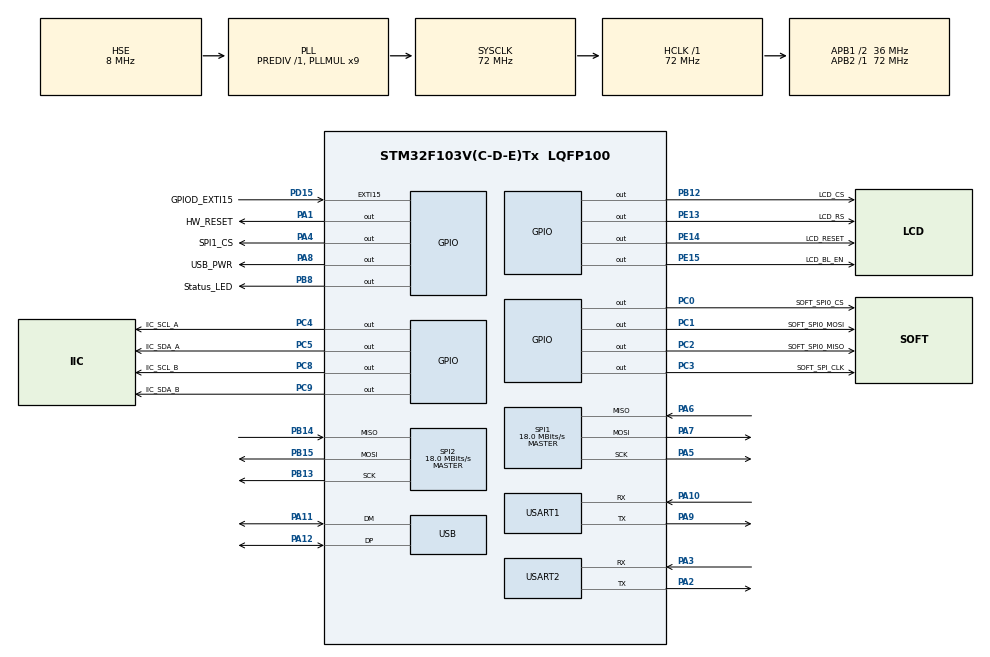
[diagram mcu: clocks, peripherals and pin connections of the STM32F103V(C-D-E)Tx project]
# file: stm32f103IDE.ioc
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FREERTOS.Tasks01=defaultTask,0,128,StartDefaultTask,Default,NULL
FREERTOS.configTOTAL_HEAP_SIZE=30720
Mcu.Family=STM32F1
Mcu.Name=STM32F103V(C-D-E)Tx
Mcu.Package=LQFP100
NVIC.PriorityGroup=NVIC_PRIORITYGROUP_4
NVIC.TIM8_UP_IRQn=true\:0\:0\:false\:false\:true\:false\:false\:true
NVIC.TimeBase=TIM8_UP_IRQn
NVIC.TimeBaseIP=TIM8
NVIC.USB_LP_CAN1_RX0_IRQn=true\:5\:0\:false\:false\:true\:true\:false\:true
OSC_IN.Mode=HSE-External-Oscillator
OSC_IN.Signal=RCC_OSC_IN
OSC_OUT.Mode=HSE-External-Oscillator
OSC_OUT.Signal=RCC_OSC_OUT
PA1.GPIO_Label=HW_RESET
PA1.Signal=GPIO_Output
PA10.Mode=Asynchronous
PA10.Signal=USART1_RX
PA11.Mode=Device
PA11.Signal=USB_DM
PA12.Mode=Device
PA12.Signal=USB_DP
PA13.Mode=Serial_Wire
PA13.Signal=SYS_JTMS-SWDIO
PA14.Mode=Serial_Wire
PA14.Signal=SYS_JTCK-SWCLK
PA2.Mode=Asynchronous
PA2.Signal=USART2_TX
PA3.Mode=Asynchronous
PA3.Signal=USART2_RX
PA4.GPIO_Label=SPI1_CS
PA4.GPIO_ModeDefaultOutputPP=GPIO_MODE_OUTPUT_PP
PA4.GPIO_Speed=GPIO_SPEED_FREQ_HIGH
PA4.PinState=GPIO_PIN_SET
PA4.Signal=GPIO_Output
PA5.Mode=Full_Duplex_Master
PA5.Signal=SPI1_SCK
PA6.Mode=Full_Duplex_Master
PA6.Signal=SPI1_MISO
PA7.Mode=Full_Duplex_Master
PA7.Signal=SPI1_MOSI
PA8.GPIO_Label=USB_PWR
PA8.GPIO_ModeDefaultOutputPP=GPIO_MODE_OUTPUT_PP
PA8.GPIO_PuPd=GPIO_PULLUP
PA8.GPIO_Speed=GPIO_SPEED_FREQ_LOW
PA8.PinState=GPIO_PIN_SET
PA8.Signal=GPIO_Output
PA9.Mode=Asynchronous
PA9.Signal=USART1_TX
PB12.GPIO_Label=LCD_CS
PB12.Signal=GPIO_Output
PB13.Mode=Full_Duplex_Master
PB13.Signal=SPI2_SCK
PB14.Mode=Full_Duplex_Master
PB14.Signal=SPI2_MISO
PB15.Mode=Full_Duplex_Master
PB15.Signal=SPI2_MOSI
PB8.GPIO_Label=Status_LED
PB8.PinState=GPIO_PIN_RESET
PB8.Signal=GPIO_Output
PC0.GPIO_Label=SOFT_SPI0_CS
PC0.GPIO_ModeDefaultOutputPP=GPIO_MODE_OUTPUT_PP
PC0.GPIO_PuPd=GPIO_NOPULL
PC0.GPIO_Speed=GPIO_SPEED_FREQ_HIGH
PC0.PinState=GPIO_PIN_SET
PC0.Signal=GPIO_Output
PC1.GPIO_Label=SOFT_SPI0_MOSI
PC1.GPIO_Speed=GPIO_SPEED_FREQ_HIGH
PC1.PinState=GPIO_PIN_RESET
PC1.Signal=GPIO_Output
PC14-OSC32_IN.Mode=LSE-External-Oscillator
PC14-OSC32_IN.Signal=RCC_OSC32_IN
PC15-OSC32_OUT.Mode=LSE-External-Oscillator
PC15-OSC32_OUT.Signal=RCC_OSC32_OUT
PC2.GPIO_Label=SOFT_SPI0_MISO
PC2.GPIO_Speed=GPIO_SPEED_FREQ_HIGH
PC2.Signal=GPIO_Output
PC3.GPIO_Label=SOFT_SPI_CLK
PC3.GPIO_ModeDefaultOutputPP=GPIO_MODE_OUTPUT_PP
PC3.GPIO_PuPd=GPIO_PULLUP
PC3.GPIO_Speed=GPIO_SPEED_FREQ_HIGH
PC3.PinState=GPIO_PIN_RESET
PC3.Signal=GPIO_Output
PC4.GPIO_Label=IIC_SCL_A
PC4.GPIO_ModeDefaultOutputPP=GPIO_MODE_OUTPUT_OD
PC4.GPIO_Speed=GPIO_SPEED_FREQ_MEDIUM
PC4.PinState=GPIO_PIN_SET
PC4.Signal=GPIO_Output
PC5.GPIO_Label=IIC_SDA_A
PC5.GPIO_ModeDefaultOutputPP=GPIO_MODE_OUTPUT_OD
PC5.GPIO_Speed=GPIO_SPEED_FREQ_HIGH
PC5.PinState=GPIO_PIN_SET
PC5.Signal=GPIO_Output
PC8.GPIO_Label=IIC_SCL_B
PC8.GPIO_ModeDefaultOutputPP=GPIO_MODE_OUTPUT_OD
PC8.GPIO_Speed=GPIO_SPEED_FREQ_HIGH
PC8.PinState=GPIO_PIN_SET
PC8.Signal=GPIO_Output
PC9.GPIO_Label=IIC_SDA_B
PC9.GPIO_ModeDefaultOutputPP=GPIO_MODE_OUTPUT_OD
PC9.GPIO_Speed=GPIO_SPEED_FREQ_HIGH
PC9.PinState=GPIO_PIN_SET
PC9.Signal=GPIO_Output
PD15.GPIO_Label=GPIOD_EXTI15
PD15.Signal=GPXTI15
PE13.GPIO_Label=LCD_RS
PE13.Signal=GPIO_Output
PE14.GPIO_Label=LCD_RESET
PE14.Signal=GPIO_Output
PE15.GPIO_Label=LCD_BL_EN
PE15.Signal=GPIO_Output
ProjectManager.HeapSize=0x600
ProjectManager.StackSize=0x400
ProjectManager.TargetToolchain=STM32CubeIDE
RCC.AHBFreq_Value=72000000
RCC.APB1CLKDivider=RCC_HCLK_DIV2
RCC.APB1Freq_Value=36000000
RCC.APB1TimFreq_Value=72000000
RCC.APB2Freq_Value=72000000
RCC.APB2TimFreq_Value=72000000
RCC.EnbaleCSS=true
RCC.HCLKFreq_Value=72000000
RCC.PLLMUL=RCC_PLL_MUL9
RCC.SYSCLKFreq_VALUE=72000000
RCC.SYSCLKSource=RCC_SYSCLKSOURCE_PLLCLK
RCC.USBFreq_Value=48000000
RCC.USBPrescaler=RCC_USBCLKSOURCE_PLL_DIV1_5
SPI1.BaudRatePrescaler=SPI_BAUDRATEPRESCALER_4
SPI1.CalculateBaudRate=18.0 MBits/s
SPI1.Direction=SPI_DIRECTION_2LINES
SPI1.Mode=SPI_MODE_MASTER
SPI1.VirtualType=VM_MASTER
SPI2.CalculateBaudRate=18.0 MBits/s
SPI2.Direction=SPI_DIRECTION_2LINES
SPI2.Mode=SPI_MODE_MASTER
SPI2.VirtualType=VM_MASTER
USART1.VirtualMode=VM_ASYNC
USART2.VirtualMode=VM_ASYNC
USB_DEVICE.CLASS_NAME_FS=MSC
USB_DEVICE.MSC_MEDIA_PACKET=0x1000
USB_DEVICE.USBD_DEBUG_LEVEL=3
USB_DEVICE.USBD_MAX_NUM_CONFIGURATION=2
USB_DEVICE.USBD_MAX_NUM_INTERFACES=2
USB_DEVICE.USBD_MAX_STR_DESC_SIZ=128
USB_DEVICE.VirtualMode=Msc
USB_DEVICE.VirtualModeFS=Msc_FS
VP_FREERTOS_VS_CMSIS_V1.Mode=CMSIS_V1
VP_SYS_VS_tim8.Mode=TIM8
VP_USB_DEVICE_VS_USB_DEVICE_MSC_FS.Mode=MSC_FS
board=custom

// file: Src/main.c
/* USER CODE BEGIN Header */
/**
  ******************************************************************************
  * @file           : main.c
  * @brief          : Main program body
  ******************************************************************************
  * @attention
  *
  * <h2><center>&copy; Copyright (c) 2019 STMicroelectronics.
  * All rights reserved.</center></h2>
  *
  * This software component is licensed by ST under BSD 3-Clause license,
  * the "License"; You may not use this file except in compliance with the
  * License. You may obtain a copy of the License at:
  *                        opensource.org/licenses/BSD-3-Clause
  *
  ******************************************************************************
  */
/* USER CODE END Header */

#include "main.h"
#include "cmsis_os.h"
#include "spi.h"
#include "usart.h"
#include "usb_device.h"
#include "gpio.h"

/* USER CODE BEGIN Includes */
#include "bsp_eeprom.h"
/* USER CODE END Includes */

void SystemClock_Config(void);
void MX_FREERTOS_Init(void);

int main(void)
{

  /* MCU Configuration--------------------------------------------------------*/

  /* Reset of all peripherals, Initializes the Flash interface and the Systick. */
  HAL_Init();

  /* Configure the system clock */
  SystemClock_Config();

  /* Initialize all configured peripherals */
  MX_GPIO_Init();
  MX_SPI1_Init();
  MX_SPI2_Init();
  MX_USART1_UART_Init();
  MX_USART2_UART_Init();
  /* USER CODE BEGIN 2 */
  printf("program start\r\n");

  //eeprom_Test();
  read_Manufacturer_Device_ID();
  //flash_Test();

  //mount_disk();
  Lcd_Init();

  printf("program end\r\n");
  /* USER CODE END 2 */

  /* Call init function for freertos objects (in freertos.c) */
  MX_FREERTOS_Init();

  /* Start scheduler */
  osKernelStart();

  /* We should never get here as control is now taken by the scheduler */

  /* Infinite loop */
  while (1)
  {

  }
}

void SystemClock_Config(void)
{
  RCC_OscInitTypeDef RCC_OscInitStruct = {0};
  RCC_ClkInitTypeDef RCC_ClkInitStruct = {0};
  RCC_PeriphCLKInitTypeDef PeriphClkInit = {0};

  /** Initializes the CPU, AHB and APB busses clocks
  */
  RCC_OscInitStruct.OscillatorType = RCC_OSCILLATORTYPE_HSE;
  RCC_OscInitStruct.HSEState = RCC_HSE_ON;
  RCC_OscInitStruct.HSEPredivValue = RCC_HSE_PREDIV_DIV1;
  RCC_OscInitStruct.HSIState = RCC_HSI_ON;
  RCC_OscInitStruct.PLL.PLLState = RCC_PLL_ON;
  RCC_OscInitStruct.PLL.PLLSource = RCC_PLLSOURCE_HSE;
  RCC_OscInitStruct.PLL.PLLMUL = RCC_PLL_MUL9;
  if (HAL_RCC_OscConfig(&RCC_OscInitStruct) != HAL_OK)
  {
    Error_Handler();
  }
  /** Initializes the CPU, AHB and APB busses clocks
  */
  RCC_ClkInitStruct.ClockType = RCC_CLOCKTYPE_HCLK|RCC_CLOCKTYPE_SYSCLK
                              |RCC_CLOCKTYPE_PCLK1|RCC_CLOCKTYPE_PCLK2;
  RCC_ClkInitStruct.SYSCLKSource = RCC_SYSCLKSOURCE_PLLCLK;
  RCC_ClkInitStruct.AHBCLKDivider = RCC_SYSCLK_DIV1;
  RCC_ClkInitStruct.APB1CLKDivider = RCC_HCLK_DIV2;
  RCC_ClkInitStruct.APB2CLKDivider = RCC_HCLK_DIV1;

  if (HAL_RCC_ClockConfig(&RCC_ClkInitStruct, FLASH_LATENCY_2) != HAL_OK)
  {
    Error_Handler();
  }
  PeriphClkInit.PeriphClockSelection = RCC_PERIPHCLK_USB;
  PeriphClkInit.UsbClockSelection = RCC_USBCLKSOURCE_PLL_DIV1_5;
  if (HAL_RCCEx_PeriphCLKConfig(&PeriphClkInit) != HAL_OK)
  {
    Error_Handler();
  }
  /** Enables the Clock Security System
  */
  HAL_RCC_EnableCSS();
}

void HAL_TIM_PeriodElapsedCallback(TIM_HandleTypeDef *htim)
{
  if (htim->Instance == TIM8) {
    HAL_IncTick();
  }
}

void Error_Handler(void)
{
  /* USER CODE BEGIN Error_Handler_Debug */
  /* User can add his own implementation to report the HAL error return state */
	printf("Error_Handler\r\n");
  /* USER CODE END Error_Handler_Debug */
}

/************************ (C) COPYRIGHT STMicroelectronics *****END OF FILE****/

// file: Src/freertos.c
/* USER CODE BEGIN Header */
/**
  ******************************************************************************
  * File Name          : freertos.c
  * Description        : Code for freertos applications
  ******************************************************************************
  * @attention
  *
  * <h2><center>&copy; Copyright (c) 2019 STMicroelectronics.
  * All rights reserved.</center></h2>
  *
  * This software component is licensed by ST under Ultimate Liberty license
  * SLA0044, the "License"; You may not use this file except in compliance with
  * the License. You may obtain a copy of the License at:
  *                             www.st.com/SLA0044
  *
  ******************************************************************************
  */
/* USER CODE END Header */

#include "FreeRTOS.h"
#include "task.h"
#include "main.h"
#include "cmsis_os.h"

osThreadId defaultTaskHandle;

void StartDefaultTask(void const * argument);

extern void MX_USB_DEVICE_Init(void);
void MX_FREERTOS_Init(void); /* (MISRA C 2004 rule 8.1) */

void MX_FREERTOS_Init(void) {

  /* Create the thread(s) */
  /* definition and creation of defaultTask */
  osThreadDef(defaultTask, StartDefaultTask, osPriorityNormal, 0, 128);
  defaultTaskHandle = osThreadCreate(osThread(defaultTask), NULL);

}

void StartDefaultTask(void const * argument)
{
  /* init code for USB_DEVICE */
  MX_USB_DEVICE_Init();

  for(;;)
  {
    osDelay(1);
  }
}

/************************ (C) COPYRIGHT STMicroelectronics *****END OF FILE****/
